# M451_v1 register map
File version: 1.0
Registers are 32-bit, read-write, reset 0x0 unless marked. A register's access mark holds for its fields unless they carry their own. Offsets are from the block's base; [hi:lo] are bit positions; 'fields as' and 'values as' point back to an identical list.

## SPI1 — SPI Register Map
Base 0x40061000
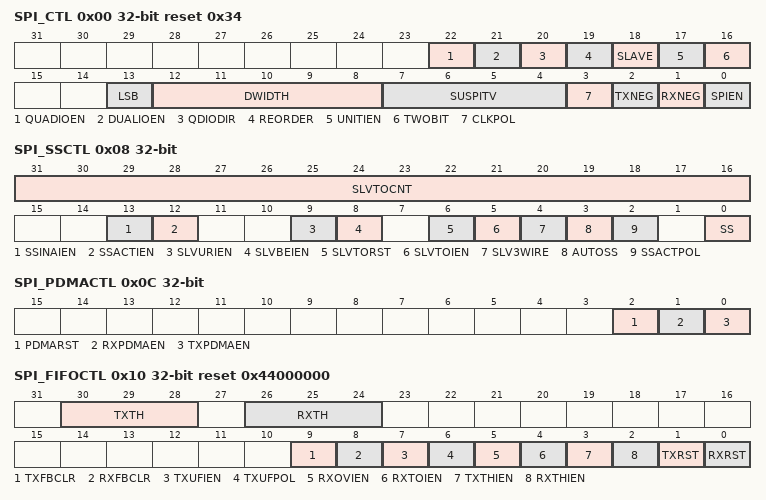
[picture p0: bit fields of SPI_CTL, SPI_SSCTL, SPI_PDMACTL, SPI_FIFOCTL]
0x00 SPI_CTL reset 0x34 — SPI Control Register
  [22] QUADIOEN — Quad I/O Mode Enable Bit (Only Supported in SPI0)
    0=Quad I/O mode Disabled; 1=Quad I/O mode Enabled
  [21] DUALIOEN — Dual I/O Mode Enable Bit (Only Supported in SPI0)
    0=Dual I/O mode Disabled; 1=Dual I/O mode Enabled
  [20] QDIODIR — Quad or Dual I/O Mode Direction Control (Only Supported in SPI0)
    0=Quad or Dual Input mode; 1=Quad or Dual Output mode
  [19] REORDER — Byte Reorder Function Enable Bit. Note: Byte Reorder function is only available if DWIDTH is defined as 16, 24, and 32 bits. Byte Reorder function is not supported when the Quad or Dual I/O mode is enabled.
    0=Byte Reorder function Disabled; 1=Byte Reorder function Enabled. A byte suspend interval will be inserted among each byte. The period of the byte suspend interval depends on the setting of SUSPITV
  [18] SLAVE — Slave Mode Control
    0=Master mode; 1=Slave mode
  [17] UNITIEN — Unit Transfer Interrupt Enable Bit
    0=SPI unit transfer interrupt Disabled; 1=SPI unit transfer interrupt Enabled
  [16] TWOBIT — 2-bit Transfer Mode Enable Bit (Only Supported in SPI0). Note: When 2-Bit Transfer mode is enabled, the first serial transmitted bit data is from the first FIFO buffer data, and the 2nd serial transmitted bit data is from the second FIFO buffer data. As the same as transmitted function, the first received bit data is stored into the first FIFO buffer and the 2nd received bit data is stored into the second FIFO buffer at the same time.
    0=2-Bit Transfer mode Disabled; 1=2-Bit Transfer mode Enabled
  [13] LSB — Send LSB First
    0=The MSB, which bit of transmit/receive register depends on the setting of DWIDTH, is transmitted/received first; 1=The LSB, bit 0 of the SPI TX register, is sent first to the SPI data output pin, and the first bit received from the SPI data input pin will be put in the LSB position of the RX register (bit 0 of SPI_RX)
  [12:8] DWIDTH — Data Width. This field specifies how many bits can be transmitted/received in one transaction. The minimum bit length is 8 bits and can up to 32 bits.
  [7:4] SUSPITV — Suspend Interval (Master Only). The four bits provide configurable suspend interval between two successive transmit/receive transaction in a transfer. The definition of the suspend interval is the interval between the last clock edge of the preceding transaction word and the first clock edge of the following transaction word. The default value is 0x3. The period of the suspend interval is obtained according to the following equation. (SUSPITV[3:0] + 0.5) * period of SPICLK clock cycle. Example:
  [3] CLKPOL — Clock Polarity
    0=SPI bus clock is idle low; 1=SPI bus clock is idle high
  [2] TXNEG — Transmit on Negative Edge
    0=Transmitted data output signal is changed on the rising edge of SPI bus clock; 1=Transmitted data output signal is changed on the falling edge of SPI bus clock
  [1] RXNEG — Receive on Negative Edge
    0=Received data input signal is latched on the rising edge of SPI bus clock; 1=Received data input signal is latched on the falling edge of SPI bus clock
  [0] SPIEN — SPI Transfer Control Enable Bit. In Master mode, the transfer will start when there is a data in the FIFO buffer after this is set to 1. In Slave mode, this device is ready to receive data when this bit is set to 1. Note: Before changing the configurations of SPI_CTL, SPI_CLKDIV, SPI_SSCTL and SPI_FIFOCTL registers, user shall clear the SPIEN (SPI_CTL[0]) and confirm the SPIENSTS (SPI_STATUS[15]) is 0.
    0=Transfer control Disabled; 1=Transfer control Enabled
0x04 SPI_CLKDIV — SPI Clock Divider Register
  [7:0] DIVIDER — Clock Divider. The value in this field is the frequency divider for generating the peripheral clock, fspi_eclk, and the SPI bus clock of SPI master. The frequency is obtained according to the following equation. where is the peripheral clock source, which is defined in the clock control register, CLK_CLKSEL2. Note: Not supported in I2S mode.
0x08 SPI_SSCTL — SPI Slave Select Control Register
  [31:16] SLVTOCNT — Slave Mode Time-out Period (Only Supported in SPI0). In Slave mode, these bits indicate the time-out period when there is bus clock input during slave select active. The clock source of the time-out counter is Slave peripheral clock. If the value is 0, it indicates the slave mode time-out function is disabled.
  [13] SSINAIEN — Slave Select Inactive Interrupt Enable Bit
    0=Slave select inactive interrupt Disabled; 1=Slave select inactive interrupt Enabled
  [12] SSACTIEN — Slave Select Active Interrupt Enable Bit
    0=Slave select active interrupt Disabled; 1=Slave select active interrupt Enabled
  [9] SLVURIEN — Slave Mode TX Under Run Interrupt Enable Bit
    0=Slave mode TX under run interrupt Disabled; 1=Slave mode TX under run interrupt Enabled
  [8] SLVBEIEN — Slave Mode Bit Count Error Interrupt Enable Bit
    0=Slave mode bit count error interrupt Disabled; 1=Slave mode bit count error interrupt Enabled
  [6] SLVTORST — Slave Mode Time-out Reset Control (Only Supported in SPI0)
    0=When Slave mode time-out event occurs, the TX and RX control circuit will not be reset; 1=When Slave mode time-out event occurs, the TX and RX control circuit will be reset by hardware
  [5] SLVTOIEN — Slave Mode Time-out Interrupt Enable Bit (Only Supported in SPI0)
    0=Slave mode time-out interrupt Disabled; 1=Slave mode time-out interrupt Enabled
  [4] SLV3WIRE — Slave 3-wire Mode Enable Bit (Only Supported in SPI0). Slave 3-wire mode is only available in SPI0. In Slave 3-wire mode, the SPI controller can work with 3-wire interface including SPI0_CLK, SPI0_MISO and SPI0_MOSI pins.
    0=4-wire bi-direction interface; 1=3-wire bi-direction interface
  [3] AUTOSS — Automatic Slave Selection Function Enable Bit (Master Only)
    0=Automatic slave selection function Disabled. Slave selection signal will be asserted/de-asserted according to SS (SPI_SSCTL[0]); 1=Automatic slave selection function Enabled
  [2] SSACTPOL — Slave Selection Active Polarity. This bit defines the active polarity of slave selection signal (SPIn_SS).
    0=The slave selection signal SPIn_SS is active low; 1=The slave selection signal SPIn_SS is active high
  [0] SS — Slave Selection Control (Master Only). If AUTOSS bit is cleared to 0,
    0=set the SPIn_SS line to inactive state. Keep the SPIn_SS line at inactive state; 1=set the SPIn_SS line to active state. SPIn_SS line will be automatically driven to active state for the duration of data transfer, and will be driven to inactive state for the rest of the time. The active state of SPIn_SS is specified in SSACTPOL (SPI_SSCTL[2])
0x0C SPI_PDMACTL — SPI PDMA Control Register
  [2] PDMARST — PDMA Reset
    0=No effect; 1=Reset the PDMA control logic of the SPI controller. This bit will be automatically cleared to 0
  [1] RXPDMAEN — Receive PDMA Enable Bit
    0=Receive PDMA function Disabled; 1=Receive PDMA function Enabled
  [0] TXPDMAEN — Transmit PDMA Enable Bit. Note: In SPI master mode with full duplex transfer, if both TX and RX PDMA functions are enabled, RX PDMA function cannot be enabled prior to TX PDMA function. User can enable TX PDMA function firstly or enable both functions simultaneously.
    0=Transmit PDMA function Disabled; 1=Transmit PDMA function Enabled
0x10 SPI_FIFOCTL reset 0x44000000 — SPI FIFO Control Register
  [30:28] TXTH — Transmit FIFO Threshold. If the valid data count of the transmit FIFO buffer is less than or equal to the TXTH setting, the TXTHIF bit will be set to 1, else the TXTHIF bit will be cleared to 0. In SPI0, TXTH is a 3-bit wide configuration; in SPI1 and SPI2, 2-bit wide only (SPI_FIFOCTL[29:28]).
  [26:24] RXTH — Receive FIFO Threshold. If the valid data count of the receive FIFO buffer is larger than the RXTH setting, the RXTHIF bit will be set to 1, else the RXTHIF bit will be cleared to 0. In SPI0, RXTH is a 3-bit wide configuration; in SPI1 and SPI2, 2-bit wide only (SPI_FIFOCTL[25:24]).
  [9] TXFBCLR — Transmit FIFO Buffer Clear. Note: The TX shift register will not be cleared.
    0=No effect; 1=Clear transmit FIFO pointer. The TXFULL bit will be cleared to 0 and the TXEMPTY bit will be set to 1. This bit will be cleared to 0 by hardware about 1 system clock after it is set to 1
  [8] RXFBCLR — Receive FIFO Buffer Clear. Note: The RX shift register will not be cleared.
    0=No effect; 1=Clear receive FIFO pointer. The RXFULL bit will be cleared to 0 and the RXEMPTY bit will be set to 1. This bit will be cleared to 0 by hardware about 1 system clock after it is set to 1
  [7] TXUFIEN — TX Underflow Interrupt Enable Bit. In Slave mode, when TX underflow event occurs, this interrupt flag will be set to 1.
    0=Slave TX underflow interrupt Disabled; 1=Slave TX underflow interrupt Enabled
  [6] TXUFPOL — TX Underflow Data Polarity. Note 1: The TX underflow event occurs if there is not any data in TX FIFO when the slave selection signal is active. Note 2: This bit should be set as 0 in I2S mode.
    0=The SPI data out is keep 0 if there is TX underflow event in Slave mode; 1=The SPI data out is keep 1 if there is TX underflow event in Slave mode
  [5] RXOVIEN — Receive FIFO Overrun Interrupt Enable Bit
    0=Receive FIFO overrun interrupt Disabled; 1=Receive FIFO overrun interrupt Enabled
  [4] RXTOIEN — Slave Receive Time-out Interrupt Enable Bit
    0=Receive time-out interrupt Disabled; 1=Receive time-out interrupt Enabled
  [3] TXTHIEN — Transmit FIFO Threshold Interrupt Enable Bit
    0=TX FIFO threshold interrupt Disabled; 1=TX FIFO threshold interrupt Enabled
  [2] RXTHIEN — Receive FIFO Threshold Interrupt Enable Bit
    0=RX FIFO threshold interrupt Disabled; 1=RX FIFO threshold interrupt Enabled
  [1] TXRST — Transmit Reset. Note: If there is slave receive time-out event, the TXRST will be set to 1 when the SLVTORST (SPI_SSCTL[6]) is enabled.
    0=No effect; 1=Reset transmit FIFO pointer and transmit circuit. The TXFULL bit will be cleared to 0 and the TXEMPTY bit will be set to 1. This bit will be cleared to 0 by hardware about 3 system clock cycles + 2 peripheral clock cycles after it is set to 1. User can read TXRXRST (SPI_STATUS[23]) to check if reset is accomplished or not
  [0] RXRST — Receive Reset. Note: If there is slave receive time-out event, the RXRST will be set 1 when the SLVTORST (SPI_SSCTL[6]) is enabled.
    0=No effect; 1=Reset receive FIFO pointer and receive circuit. The RXFULL bit will be cleared to 0 and the RXEMPTY bit will be set to 1. This bit will be cleared to 0 by hardware about 3 system clock cycles + 2 peripheral clock cycles after it is set to 1. User can read TXRXRST (SPI_STATUS[23]) to check if reset is accomplished or not
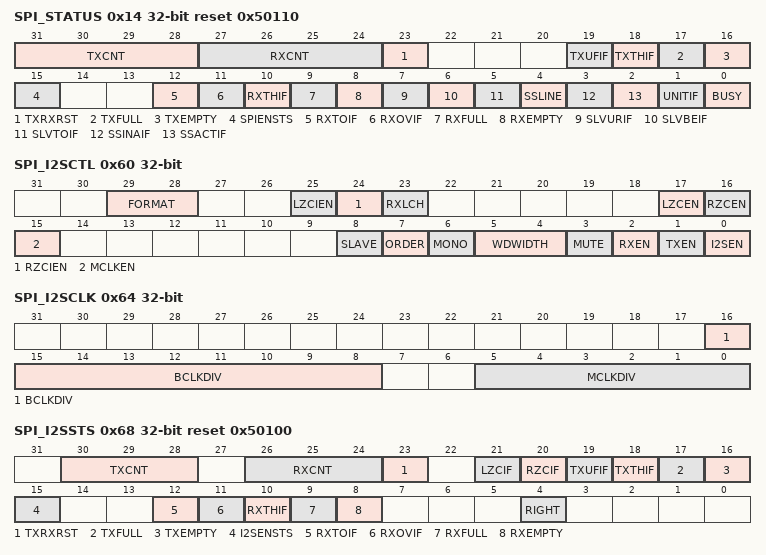
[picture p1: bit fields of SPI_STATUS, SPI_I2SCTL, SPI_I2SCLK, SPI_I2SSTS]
0x14 SPI_STATUS reset 0x50110
  [31:28] TXCNT ro — Transmit FIFO Data Count (Read Only). This bit field indicates the valid data count of transmit FIFO buffer.
  [27:24] RXCNT ro — Receive FIFO Data Count (Read Only). This bit field indicates the valid data count of receive FIFO buffer.
  [23] TXRXRST ro — TX or RX Reset Status (Read Only). Note: Both the reset operations of TXRST and RXRST need 3 system clock cycles + 2 peripheral clock cycles. User can check the status of this bit to monitor the reset function is doing or done.
    0=The reset function of TXRST or RXRST is done; 1=Doing the reset function of TXRST or RXRST
  [19] TXUFIF — TX Underflow Interrupt Flag. When the TX underflow event occurs, this bit will be set to 1, the state of data output pin depends on the setting of TXUFPOL. Note 1: This bit will be cleared by writing 1 to it. Note 2: If reset slave's transmission circuit when slave selection signal is active, this flag will be set to 1 after 3 system clock cycles + 2 peripheral clock cycles since the reset operation is done.
    0=No effect; 1=No data in Transmit FIFO and TX shift register when the slave selection signal is active
  [18] TXTHIF ro — Transmit FIFO Threshold Interrupt Flag (Read Only)
    0=The valid data count within the transmit FIFO buffer is larger than the setting value of TXTH; 1=The valid data count within the transmit FIFO buffer is less than or equal to the setting value of TXTH
  [17] TXFULL ro — Transmit FIFO Buffer Full Indicator (Read Only)
    0=Transmit FIFO buffer is not full; 1=Transmit FIFO buffer is full
  [16] TXEMPTY ro — Transmit FIFO Buffer Empty Indicator (Read Only)
    0=Transmit FIFO buffer is not empty; 1=Transmit FIFO buffer is empty
  [15] SPIENSTS ro — SPI Enable Status (Read Only). Note: The SPI peripheral clock is asynchronous with the system clock. In order to make sure the SPI control logic is disabled, this bit indicates the real status of SPI controller.
    0=The SPI controller is disabled; 1=The SPI controller is enabled
  [12] RXTOIF — Receive Time-out Interrupt Flag. Note: This bit will be cleared by writing 1 to it.
    0=No receive FIFO time-out event; 1=Receive FIFO buffer is not empty and no read operation on receive FIFO buffer over 64 SPI clock period in Master mode or over 576 peripheral clock period in Slave mode. When the received FIFO buffer is read by software, the time-out status will be cleared automatically
  [11] RXOVIF — Receive FIFO Overrun Interrupt Flag. When the receive FIFO buffer is full, the follow-up data will be dropped and this bit will be set to 1. Note: This bit will be cleared by writing 1 to it.
    0=Receive FIFO does not over run; 1=Receive FIFO over run
  [10] RXTHIF ro — Receive FIFO Threshold Interrupt Flag (Read Only)
    0=The valid data count within the RX FIFO buffer is smaller than or equal to the setting value of RXTH; 1=The valid data count within the receive FIFO buffer is larger than the setting value of RXTH
  [9] RXFULL ro — Receive FIFO Buffer Full Indicator (Read Only)
    0=Receive FIFO buffer is not full; 1=Receive FIFO buffer is full
  [8] RXEMPTY ro — Receive FIFO Buffer Empty Indicator (Read Only)
    0=Receive FIFO buffer is not empty; 1=Receive FIFO buffer is empty
  [7] SLVURIF — Slave Mode TX Under Run Interrupt Flag. In Slave mode, if TX underflow event occurs and the slave select line goes to inactive state, this interrupt flag will be set to 1. Note: This bit will be cleared by writing 1 to it.
    0=No Slave TX under run event; 1=Slave TX under run event occurs
  [6] SLVBEIF — Slave Mode Bit Count Error Interrupt Flag. In Slave mode, when the slave select line goes to inactive state, if bit counter is mismatch with DWIDTH, this interrupt flag will be set to 1. Note: If the slave select active but there is no any bus clock input, the SLVBCEIF also be set when the slave select goes to inactive state. This bit will be cleared by writing 1 to it.
    0=No Slave mode bit count error event; 1=Slave mode bit count error event occurs
  [5] SLVTOIF — Slave Time-out Interrupt Flag (Only Supported in SPI0). When the slave select is active and the value of SLVTOCNT is not 0, as the bus clock is detected, the slave time-out counter in SPI controller logic will be started. When the value of time-out counter is greater than or equal to the value of SLVTOCNT (SPI_SSCTL[31:16]) before one transaction is done, the slave time-out interrupt event will be asserted. Note: This bit will be cleared by writing 1 to it.
    0=Slave time-out is not active; 1=Slave time-out is active
  [4] SSLINE ro — Slave Select Line Bus Status (Read Only). Note: This bit is only available in Slave mode. If SSACTPOL (SPI_SSCTL[2]) is set 0, and the SSLINE is 1, the SPI slave select is in inactive status.
    0=The slave select line status is 0; 1=The slave select line status is 1
  [3] SSINAIF — Slave Select Inactive Interrupt Flag. Note: Only available in Slave mode. This bit will be cleared by writing 1 to it.
    0=Slave select inactive interrupt be cleared or not occurrs; 1=Slave select inactive interrupt event occurrs
  [2] SSACTIF — Slave Select Active Interrupt Flag. Note: Only available in Slave mode. This bit will be cleared by writing 1 to it.
    0=Slave select active interrupt be cleared or not occurrs; 1=Slave select active interrupt event occurrs
  [1] UNITIF — Unit Transfer Interrupt Flag. Note: This bit will be cleared by writing 1 to it.
    0=No transaction has been finished since this bit was cleared to 0; 1=SPI controller has finished one unit transfer
  [0] BUSY ro — Busy Status (Read Only)
    0=SPI controller is in idle state; 1=SPI controller is in busy state
0x20 SPI_TX wo — Data Transmit Register
  [31:0] TX — Data Transmit Register. The data transmit registers pass through the transmitted data into the 8-/4-level transmit FIFO buffer. The number of valid bits depends on the setting of DWIDTH (SPI_CTL[12:8]) in SPI mode or WDWIDTH (SPI_I2SCTL[5:4]) in I2S mode. For example, if DWIDTH is set to 0x08, the bits TX[7:0] will be transmitted. If DWIDTH is set to 0x00, the SPI controller will perform a 32-bit transfer. Note: In Master mode, SPI controller will start to transfer after 1 APB clock cycle and 6 peripheral clock cycles after user writes to this register.
0x30 SPI_RX ro — Data Receive Register
  [31:0] RX — Data Receive Register. There are 8-/4-level FIFO buffers in this controller. The data receive register holds the data received from SPI data input pin. If the RXEMPTY (SPI_STATUS[8] or SPI_I2SSTS[8]) is not set to 1, the receive FIFO buffers can be accessed through software by reading this register. This is a read only register.
0x60 SPI_I2SCTL — I2S Control Register
  [29:28] FORMAT — Data Format Selection
    0=I2S data format; 1=MSB justified data format; 2=PCM mode A; 3=PCM mode B
  [25] LZCIEN — Left Channel Zero-cross Interrupt Enable Bit. Interrupt occurs if this bit is set to 1 and left channel zero-cross event occurs.
    0=Interrupt Disabled; 1=Interrupt Enabled
  [24] RZCIEN — Right Channel Zero-cross Interrupt Enable Bit. Interrupt occurs if this bit is set to 1 and right channel zero-cross event occurs.
    0=Interrupt Disabled; 1=Interrupt Enabled
  [23] RXLCH — Receive Left Channel Enable Bit
    0=Receive right channel data in Mono mode; 1=Receive left channel data in Mono mode
  [17] LZCEN — Left Channel Zero Cross Detection Enable Bit. If this bit is set to 1, when left channel data sign bit changes or next shift data bits are all 0 then LZCIF flag in SPI_I2SSTS register will be set to 1. This function is only available in transmit operation.
    0=Left channel zero cross detection Disabled; 1=Left channel zero cross detection Enabled
  [16] RZCEN — Right Channel Zero Cross Detection Enable Bit. If this bit is set to 1, when right channel data sign bit change or next shift data bits are all 0 then RZCIF flag in SPI_I2SSTS register will be set to 1. This function is only available in transmit operation.
    0=Right channel zero cross detection Disabled; 1=Right channel zero cross detection Enabled
  [15] MCLKEN — Master Clock Enable Bit. If MCLKEN is set to 1, I2S controller will generate master clock on SPIn_I2SMCLK pin for external audio devices.
    0=Master clock Disabled; 1=Master clock Enabled
  [8] SLAVE — Slave Mode. I2S can operate as master or slave. For Master mode, I2Sn_BCLK and I2Sn_LRCLK pins are output mode and send bit clock from this chip to Audio CODEC chip. In Slave mode, I2Sn_BCLK and I2Sn_LRCLK pins are input mode and I2Sn_BCLK and I2Sn_LRCLK signals are received from outer Audio CODEC chip.
    0=Master mode; 1=Slave mode
  [7] ORDER — Stereo Data Order in FIFO
    0=Left channel data at high byte; 1=Left channel data at low byte
  [6] MONO — Monaural Data
    0=Data is stereo format; 1=Data is monaural format
  [5:4] WDWIDTH — Word Width
    0=data size is 8-bit; 1=data size is 16-bit; 2=data size is 24-bit; 3=data size is 32-bit
  [3] MUTE — Transmit Mute Enable Bit
    0=Transmit data is shifted out from buffer; 1=Transmit data is zero
  [2] RXEN — Receive Enable Bit
    0=Data receive Disabled; 1=Data receive Enabled
  [1] TXEN — Transmit Enable Bit
    0=Data transmit Disabled; 1=Data transmit Enabled
  [0] I2SEN — I2S Controller Enable Bit. Note: If set this bit to 1, I2Sn_BCLK will start to output in master mode.
    0=I2S controller Disabled; 1=I2S controller Enabled
0x64 SPI_I2SCLK — I2S Clock Divider Control Register
  [16:8] BCLKDIV — Bit Clock Divider. The I2S controller will generate bit clock in Master mode. The bit clock rate, F_I2SBCLK, is determined by the following expression.
  [5:0] MCLKDIV — Master Clock Divider. If MCLKEN is set to 1, I2S controller will generate master clock for external audio devices. The master clock rate, F_I2SMCLK, is determined by the following expressions. F_I2SCLK is the frequency of I2S source clock determined by SPInSEL setting of CLK_CLKSEL2 register. In general, the master clock rate is 256 times sampling clock rate.
0x68 SPI_I2SSTS reset 0x50100 — I2S Status Register
  [30:28] TXCNT ro — Transmit FIFO Data Count (Read Only). This bit field indicates the valid data count of transmit FIFO buffer.
  [26:24] RXCNT ro — Receive FIFO Data Count (Read Only). This bit field indicates the valid data count of receive FIFO buffer.
  [23] TXRXRST ro — TX or RX Reset Status (Read Only). Note: Both the reset operations of TXRST and RXRST need 3 system clock cycles + 3 peripheral clock cycles. User can check the status of this bit to monitor the reset function is doing or done.
    values as SPI_STATUS.TXRXRST
  [21] LZCIF — Left Channel Zero Cross Interrupt Flag
    0=No zero cross event occurred on left channel; 1=Zero cross event occurred on left channel
  [20] RZCIF — Right Channel Zero Cross Interrupt Flag
    0=No zero cross event occurred on right channel; 1=Zero cross event occurred on right channel
  [19] TXUFIF — Transmit FIFO Underflow Interrupt Flag. When the transmit FIFO buffer is empty and there is no datum written into the FIFO buffer, if there is more bus clock input, this bit will be set to 1. Note: This bit will be cleared by writing 1 to it.
  [18] TXTHIF ro — Transmit FIFO Threshold Interrupt Flag (Read Only)
    values as SPI_STATUS.TXTHIF
  [17] TXFULL ro — Transmit FIFO Buffer Full Indicator (Read Only)
    values as SPI_STATUS.TXFULL
  [16] TXEMPTY ro — Transmit FIFO Buffer Empty Indicator (Read Only)
    values as SPI_STATUS.TXEMPTY
  [15] I2SENSTS ro — I2S Enable Status (Read Only). Note: The SPI/I2S peripheral clock is asynchronous with the system clock. In order to make sure the SPI/I2S controller logic is disabled, this bit indicates the real status of SPI/I2S controller logic for user.
    0=The SPI/I2S control logic is disabled; 1=The SPI/I2S control logic is enabled
  [12] RXTOIF — Receive Time-out Interrupt Flag. Note: This bit will be cleared by writing 1 to it.
    values as SPI_STATUS.RXTOIF
  [11] RXOVIF — Receive FIFO Overrun Interrupt Flag. When the receive FIFO buffer is full, the follow-up data will be dropped and this bit will be set to 1. Note: This bit will be cleared by writing 1 to it.
  [10] RXTHIF ro — Receive FIFO Threshold Interrupt Flag (Read Only)
    0=The valid data count within the Rx FIFO buffer is smaller than or equal to the setting value of RXTH; 1=The valid data count within the receive FIFO buffer is larger than the setting value of RXTH
  [9] RXFULL ro — Receive FIFO Buffer Full Indicator (Read Only)
    values as SPI_STATUS.RXFULL
  [8] RXEMPTY ro — Receive FIFO Buffer Empty Indicator (Read Only)
    values as SPI_STATUS.RXEMPTY
  [4] RIGHT ro — Right Channel (Read Only). This bit indicates the current transmit data is belong to which channel.
    0=Left channel; 1=Right channel

## SPI2 — SPI Register Map
Base 0x40062000
Registers as SPI1; these are added or differ:
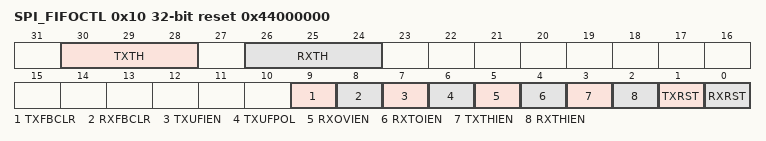
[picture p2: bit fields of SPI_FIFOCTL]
0x10 SPI_FIFOCTL reset 0x44000000 — SPI FIFO Control Register
  fields as SPI1.SPI_FIFOCTL
